# GD32H71x_72x register map
File version: 1.0
CPU: CM7 r1p2, little endian, MPU, FPU, 4 interrupt priority bits
Registers are 32-bit, read-write, reset 0x0 unless marked. A register's access mark holds for its fields unless they carry their own. Offsets are from the block's base; [hi:lo] are bit positions; {n}, {i} and the like mark numbered series.

## TIMER0 — Advanced-timers
Base 0x40010000
Same registers: TIMER7 0x40010400, TIMER19 0x40010800
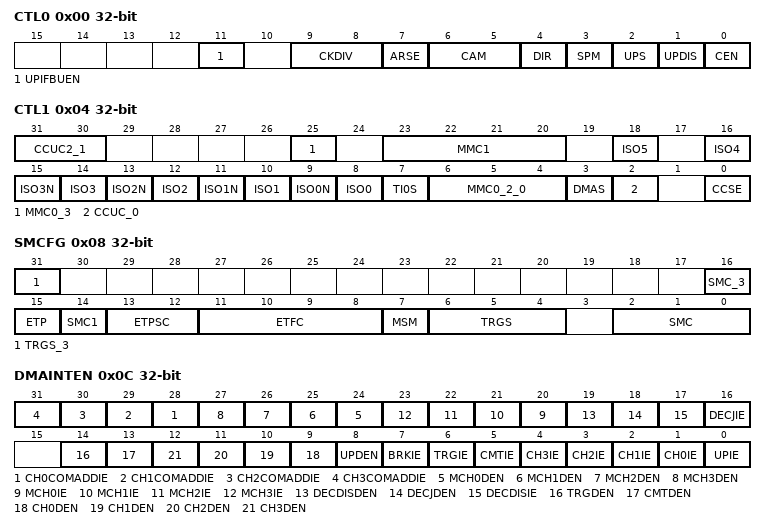
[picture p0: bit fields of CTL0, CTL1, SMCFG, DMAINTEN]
0x00 CTL0 — Control register 0
  [11] UPIFBUEN — UPIF bit backup enable
  [9:8] CKDIV — Clock division
  [7] ARSE — Auto-reload shadow enable
  [6:5] CAM — Counter align mode selection
  [4] DIR — Direction
  [3] SPM — Single pulse mode
  [2] UPS — Update source
  [1] UPDIS — Update disable
  [0] CEN — Counter enable
0x04 CTL1 — Control register 1
  [31:30] CCUC2_1 — Commutation control shadow register update control
  [25] MMC0_3 — Master mode control 0
  [23:20] MMC1 — Master mode control 1
  [18] ISO5 — Idle state of channel 5 output.
  [16] ISO4 — Idle state of channel 4 output.
  [15] ISO3N — Idle state of multi mode channel 3 complementary output.
  [14] ISO3 — Idle state of channel 3 output.
  [13] ISO2N — Idle state of multi mode channel 2 complementary output.
  [12] ISO2 — Idle state of channel 2 output
  [11] ISO1N — Idle state of multi mode channel 1 complementary output
  [10] ISO1 — Idle state of channel 1 output
  [9] ISO0N — Idle state of multi mode channel 0 complementary output
  [8] ISO0 — Idle state of channel 0 output
  [7] TI0S — Channel 0 trigger input selection
  [6:4] MMC0_2_0 — Master mode control 0
  [3] DMAS — DMA request source selection
  [2] CCUC_0 — Commutation control shadow register update control
  [0] CCSE — Commutation control shadow enable
0x08 SMCFG — Slave mode configuration register
  [31] TRGS_3 — Bit 3 of trigger selection
  [16] SMC_3 — Bit 3 of slave mode control
  [15] ETP — External trigger polarity
  [14] SMC1 — Part of SMC is used to enable external clock mode 1
  [13:12] ETPSC — External trigger prescaler
  [11:8] ETFC — External trigger filter control
  [7] MSM — Master-slave mode
  [6:4] TRGS — Trigger selection
  [2:0] SMC — Slave mode control
0x0C DMAINTEN — DMA and interrupt enable register
  [n+28] CH{n}COMADDIE (n=0..3) — Channel {n} additional compare interrupt enable
  [n+24] MCH{n}DEN (n=0..3) — Multi mode channel {n} capture/compare DMA request enable
  [n+20] MCH{n}IE (n=0..3) — Multi mode channel {n} capture/compare interrupt enable
  [19] DECDISDEN — Quadrature decoder signal disconnection detection enable
  [18] DECJDEN — Quadrature decoder signal jump (the two signals jump at the same time) detection enable
  [17] DECDISIE — Quadrature decoder signal disconnection interrupt enable
  [16] DECJIE — Quadrature decoder signal jump (the two signals jump at the same time) interrupt enable
  [14] TRGDEN — Trigger DMA request enable
  [13] CMTDEN — Commutation DMA request enable
  [n+9] CH{n}DEN (n=0..3) — Channel {n} capture/compare DMA request enable
  [8] UPDEN — Update DMA request enable
  [7] BRKIE — Break interrupt enable
  [6] TRGIE — Trigger interrupt enable
  [5] CMTIE — Commutation interrupt enable
  [n+1] CH{n}IE (n=0..3) — Channel {n} capture/compare interrupt enable
  [0] UPIE — Update interrupt enable
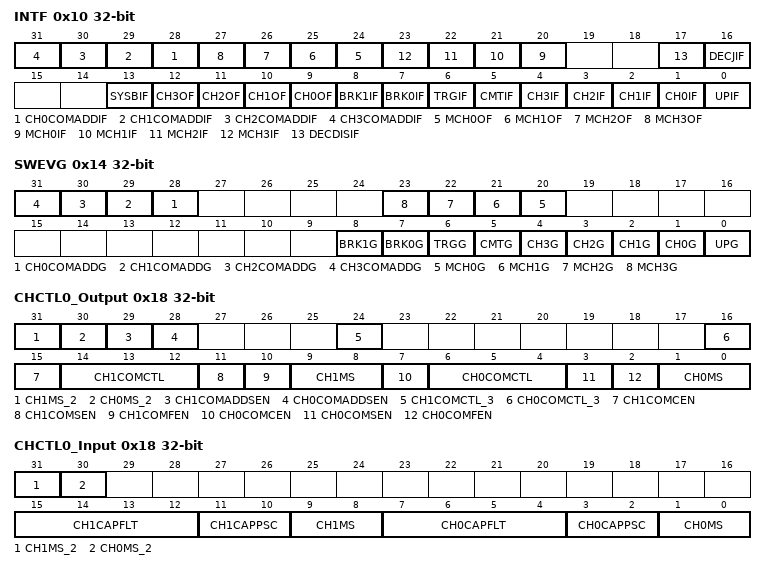
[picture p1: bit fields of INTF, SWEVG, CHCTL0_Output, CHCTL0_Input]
0x10 INTF — Interrupt flag register
  [n+28] CH{n}COMADDIF (n=0..3) — Channel {n} additional compare interrupt flag
  [n+24] MCH{n}OF (n=0..3) — Multi mode channel {n} over capture flag
  [n+20] MCH{n}IF (n=0..3) — Multi mode channel {n} capture/compare interrupt flag
  [17] DECDISIF — Quadrature decoder signal disconnection interrupt flag
  [16] DECJIF — Quadrature decoder signal jump (the two signals jump at the same time) interrupt flag
  [13] SYSBIF
  [n+9] CH{n}OF (n=0..3) — Channel {n} over capture flag
  [8] BRK1IF — Break1 interrupt flag
  [7] BRK0IF — Break0 interrupt flag
  [6] TRGIF — Trigger interrupt flag
  [5] CMTIF — Channel commutation interrupt flag
  [n+1] CH{n}IF (n=0..3) — Channel {n} capture/compare interrupt flag
  [0] UPIF — Update interrupt flag
0x14 SWEVG wo — Software event generation register
  [n+28] CH{n}COMADDG (n=0..3) — Channel {n} additional compare event generation
  [n+20] MCH{n}G (n=0..3) — Multi mode channel {n} capture or compare event generation
  [8] BRK1G — Break1 event generation
  [7] BRK0G — Break0 event generation
  [6] TRGG — Trigger event generation
  [5] CMTG — Channel commutation event generation
  [n+1] CH{n}G (n=0..3) — Channel {n} capture or compare event generation
  [0] UPG — Update event generation
0x18 CHCTL0_Output — Channel control register 0 (output mode)
  [31] CH1MS_2 — 2th bit of CH1MS
  [30] CH0MS_2 — 2th bit of CH0MS
  [29] CH1COMADDSEN — Channel 1 additional compare output shadow enable
  [28] CH0COMADDSEN — Channel 0 additional compare output shadow enable
  [24] CH1COMCTL_3 — Bit 3 of channel 1 compare output control
  [16] CH0COMCTL_3 — Bit 3 of channel 0 compare output control
  [15] CH1COMCEN — Channel 1 output compare clear enable
  [14:12] CH1COMCTL — Channel 1 compare output control
  [11] CH1COMSEN — Channel 1 output compare shadow enable
  [10] CH1COMFEN — Channel 1 output compare fast enable
  [9:8] CH1MS — Channel 1 mode selection
  [7] CH0COMCEN — Channel 0 output compare clear enable
  [6:4] CH0COMCTL — Channel 0 compare output control
  [3] CH0COMSEN — Channel 0 compare output shadow enable
  [2] CH0COMFEN — Channel 0 compare output fast enable
  [1:0] CH0MS — Channel 0 I/O mode selection
0x18 CHCTL0_Input (alternate view of CHCTL0_Output) — Channel control register 0 (input mode)
  [31] CH1MS_2 — 2th bit of CH1MS
  [30] CH0MS_2 — 2th bit of CH0MS
  [15:12] CH1CAPFLT — Channel 1 input capture filter control
  [11:10] CH1CAPPSC — Channel 1 input capture prescaler
  [9:8] CH1MS — Channel 1 mode selection
  [7:4] CH0CAPFLT — Channel 0 input capture filter control
  [3:2] CH0CAPPSC — Channel 0 input capture prescaler
  [1:0] CH0MS — Channel 0 mode selection
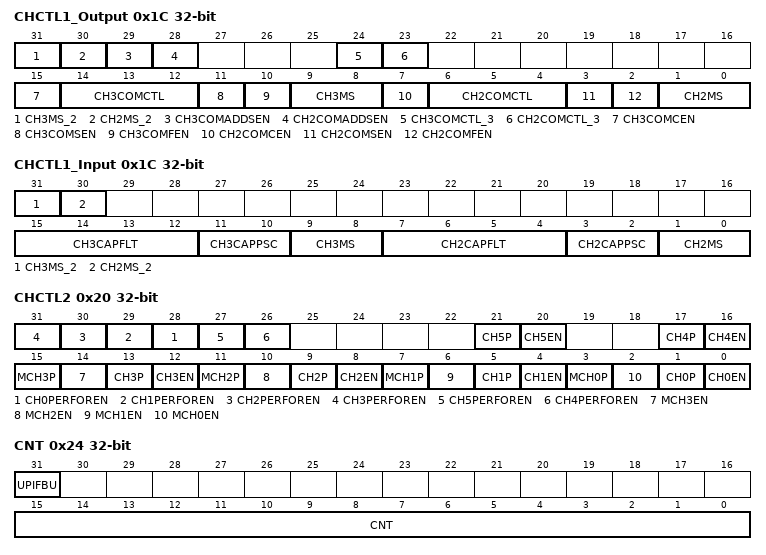
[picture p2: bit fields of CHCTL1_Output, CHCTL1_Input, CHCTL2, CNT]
0x1C CHCTL1_Output — Channel control register 1 (output mode)
  [31] CH3MS_2 — 2th bit of CH3MS
  [30] CH2MS_2 — 2th bit of CH2MS
  [29] CH3COMADDSEN — Channel 3 additional compare output shadow enable
  [28] CH2COMADDSEN — Channel 2 additional compare output shadow enable
  [24] CH3COMCTL_3 — BIT 3 of channel 3 compare output control
  [23] CH2COMCTL_3 — BIT 3 of channel 2 compare output control
  [15] CH3COMCEN — Channel 3 output compare clear enable
  [14:12] CH3COMCTL — Channel 3 compare output control
  [11] CH3COMSEN — Channel 3 output compare shadow enable
  [10] CH3COMFEN — Channel 3 output compare fast enable
  [9:8] CH3MS — Channel 3 mode selection
  [7] CH2COMCEN — Channel 2 output compare clear enable
  [6:4] CH2COMCTL — Channel 2 compare output control
  [3] CH2COMSEN — Channel 2 compare output shadow enable
  [2] CH2COMFEN — Channel 2 compare output fast enable
  [1:0] CH2MS — Channel 2 mode selection
0x1C CHCTL1_Input (alternate view of CHCTL1_Output) — Channel control register 1 (input mode)
  [31] CH3MS_2 — 2th bit of CH3MS
  [30] CH2MS_2 — 2th bit of CH2MS
  [15:12] CH3CAPFLT — Channel 3 input capture filter control
  [11:10] CH3CAPPSC — Channel 3 input capture prescaler
  [9:8] CH3MS — Channel 3 mode selection
  [7:4] CH2CAPFLT — Channel 2 input capture filter control
  [3:2] CH2CAPPSC — Channel 2 input capture prescaler
  [1:0] CH2MS — Channel 2 mode selection
0x20 CHCTL2 — Channel control register 2
  [n+28] CH{n}PERFOREN (n=0..3) — Channel {n} in the composite PWM mode or asymmetric PWM mode, the period point match moment O{n}CPRE level setting
  [27] CH5PERFOREN — Channel 5 in the composite PWM mode or asymmetric PWM mode, the period point match moment O5CPRE level setting
  [26] CH4PERFOREN — Channel 4 in the composite PWM mode or asymmetric PWM mode, the period point match moment O4CPRE level setting
  [4n+1] CH{n}P (n=0..5) — Channel {n} capture/compare polarity
  [4n] CH{n}EN (n=0..5) — Channel {n} capture/compare enable
  [15] MCH3P — Multi mode channel 3 capture/compare polarity
  [14] MCH3EN — Multi mode channel 3 capture/compare enable
  [11] MCH2P — Multi mode channel 2 output polarity
  [10] MCH2EN — Multi mode channel 2 output enable
  [7] MCH1P — Multi mode channel 1 output polarity
  [6] MCH1EN — Multi mode channel 1 output enable
  [3] MCH0P — Multi mode channel 0 output polarity
  [2] MCH0EN — Multi mode channel 0 capture/compare enable
0x24 CNT — counter
  [31] UPIFBU — UPIF bit backup
  [15:0] CNT — current counter value
0x28 PSC — prescaler
  [15:0] PSC — Prescaler value of the counter clock
0x2C CAR — Counter auto reload register
  [15:0] CARL — Counter auto reload value
0x30 CREP0 — Counter repetition register
  [7:0] CREP0 — Counter repetition value
0x34 CH0CV — Channel 0 capture/compare value register
  [15:0] CH0VAL — Capture or compare value of channel0
0x38 CH1CV — Channel 1 capture/compare value register
  [15:0] CH1VAL — Capture or compare value of channel1
0x3C CH2CV — Channel 2 capture/compare value register
  [15:0] CH2VAL — Capture or compare value of channel 2
0x40 CH3CV — Channel 3 capture/compare value register
  [15:0] CH3VAL — Capture or compare value of channel 3
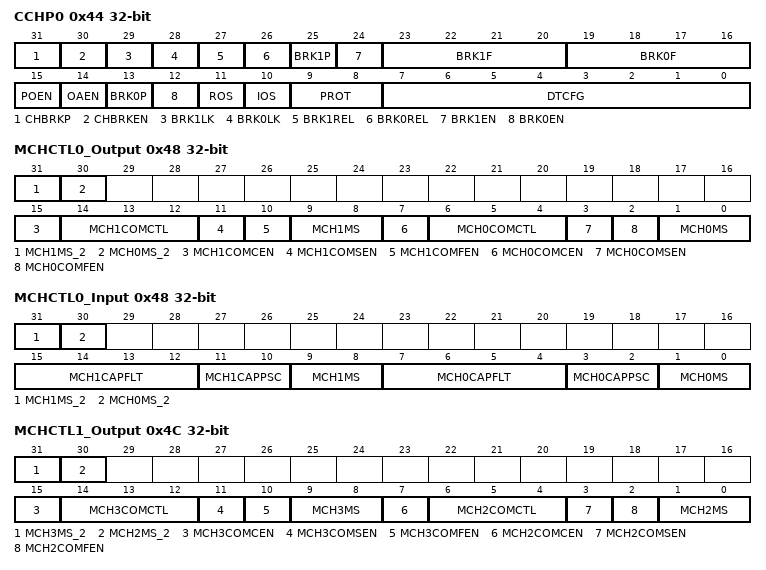
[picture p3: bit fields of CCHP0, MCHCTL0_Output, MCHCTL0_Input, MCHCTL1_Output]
0x44 CCHP0 — Complementary channel protection register 0
  [31] CHBRKP — Channel BREAK input signal polarity
  [30] CHBRKEN — Channel BREAK input signal enable
  [29] BRK1LK — BREAK1 input locked
  [28] BRK0LK — BREAK0 input locked
  [27] BRK1REL — BREAK1 input released
  [26] BRK0REL — BREAK0 input released
  [25] BRK1P — BREAK1 input signal polarity
  [24] BRK1EN — BREAK1 input signal enable
  [23:20] BRK1F — BREAK1 input signal filter
  [19:16] BRK0F — BREAK0 and channel BREAK input signal filter
  [15] POEN — Primary output enable
  [14] OAEN — Output automatic enable
  [13] BRK0P — BREAK0 input signal polarity
  [12] BRK0EN — BREAK0 input signal enable
  [11] ROS — Run mode off-state enable
  [10] IOS — Idle mode off-state enable
  [9:8] PROT — Complementary register protect control
  [7:0] DTCFG — Dead time configuration
0x48 MCHCTL0_Output — Multi mode channel control register 0 (output mode)
  [31] MCH1MS_2 — Multi mode channel 1 I/O mode selection
  [30] MCH0MS_2 — Multi mode channel 0 I/O mode selection
  [15] MCH1COMCEN — Multi mode channel 1 output compare clear enable
  [14:12] MCH1COMCTL — Multi mode channel 1 compare output control
  [11] MCH1COMSEN — Multi mode channel 1 output compare shadow enable
  [10] MCH1COMFEN — Multi mode channel 1 output compare fault enable
  [9:8] MCH1MS — Multi mode channel 1 I/O mode selection
  [7] MCH0COMCEN — Multi mode channel 0 output compare clear enable
  [6:4] MCH0COMCTL — Multi mode channel 0 output compare control
  [3] MCH0COMSEN — Multi mode channel 0 output compare shadow enable
  [2] MCH0COMFEN — Multi mode channel 0 output compare fault enable
  [1:0] MCH0MS — Multi mode channel 0 I/O mode selection
0x48 MCHCTL0_Input (alternate view of MCHCTL0_Output) — Multi mode channel control register 0 (input mode)
  [31] MCH1MS_2 — Multi mode channel 1 I/O mode selection
  [30] MCH0MS_2 — Multi mode channel 0 I/O mode selection
  [15:12] MCH1CAPFLT — Multi mode channel 1 input capture filter control
  [11:10] MCH1CAPPSC — Multi mode channel 1 input capture prescaler
  [9:8] MCH1MS — Multi mode channel 1 I/O mode selection
  [7:4] MCH0CAPFLT — Multi mode channel 0 input capture filter control
  [3:2] MCH0CAPPSC — Multi mode channel 0 input capture prescaler
  [1:0] MCH0MS — Multi mode channel 0 I/O mode selection
0x4C MCHCTL1_Output — Multi mode channel control register 1 (output mode)
  [31] MCH3MS_2 — 2th bit of MCH3MS
  [30] MCH2MS_2 — 2th bit of MCH2MS
  [15] MCH3COMCEN — Multi mode channel 3 output compare clear enable
  [14:12] MCH3COMCTL — Multi mode channel 3 compare output control
  [11] MCH3COMSEN — Multi mode channel 3 output compare shadow enable
  [10] MCH3COMFEN — Multi mode channel 3 output compare fast enable
  [9:8] MCH3MS — Multi mode channel 3 I/O mode selection
  [7] MCH2COMCEN — Multi mode channel 2 output compare clear enable
  [6:4] MCH2COMCTL — Multi mode channel 2 compare output control
  [3] MCH2COMSEN — Multi mode channel 2 output compare shadow enable
  [2] MCH2COMFEN — Multi mode channel 2 output compare fast enable
  [1:0] MCH2MS — Multi mode channel 2 I/O mode selection
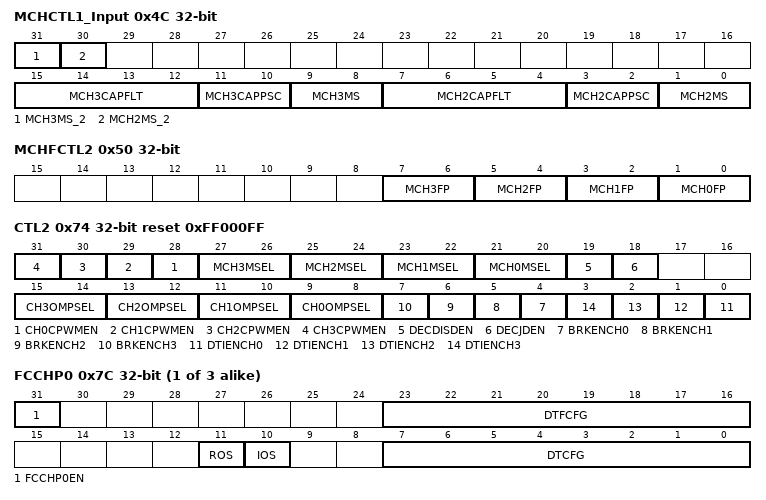
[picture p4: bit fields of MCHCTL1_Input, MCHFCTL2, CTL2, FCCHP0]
0x4C MCHCTL1_Input (alternate view of MCHCTL1_Output) — Multi mode channel control register 1(input mode)
  [31] MCH3MS_2 — 2th bit of MCH3MS
  [30] MCH2MS_2 — 2th bit of MCH2MS
  [15:12] MCH3CAPFLT — Multi mode channel 3 input capture filter control
  [11:10] MCH3CAPPSC — Multi mode channel 3 input capture prescaler
  [9:8] MCH3MS — Multi mode channel 3 I/O mode selection.
  [7:4] MCH2CAPFLT — Multi mode channel 2 input capture filter control
  [3:2] MCH2CAPPSC — Multi mode channel 2 input capture prescaler
  [1:0] MCH2MS — Multi mode channel 2 I/O mode selection
0x50 MCHFCTL2 — Multi mode channel control register 2
  [2n+1:2n] MCH{n}FP (n=0..3) — Multi mode channel {n} capture/compare free polarity
{0x54+4i} MCH{i}CV (i=0..2) — Multi mode channel {i} capture/compare value register
  [15:0] MCH{i}VAL — Capture/compare value of multi mode channel {i}
0x60 MCH3CV — Capture/compare value of multi mode channel 3
  [15:0] MCH3VAL — Capture/compare value of channel 3
{0x64+4i} CH{i}COMV_ADD (i=0..3) — Channel {i} additional compare value register
  [15:0] CH{i}COMVAL_ADD — Additional compare value of channel {i}
0x74 CTL2 reset 0xFF000FF — Control register 2
  [n+28] CH{n}CPWMEN (n=0..3) — Channel {n} composite PWM mode enable
  [2n+21:2n+20] MCH{n}MSEL (n=0..3) — Multi mode channel {n} mode select
  [19] DECDISDEN — Quadrature decoder signal disconnection detection enable
  [18] DECJDEN — Quadrature decoder signal jump (the two signals jump at the same time) detection enable
  [2n+9:2n+8] CH{n}OMPSEL (n=0..3) — Channel {n} output match pulse select
  [n+4] BRKENCH{n} (n=0..3) — Break control enable for channel {n}
  [n] DTIENCH{n} (n=0..3) — Dead time inserted enable for channel {n}
{0x7C+4i} FCCHP{i} (i=0..2) — Free complementary channel protection register {i}
  [31] FCCHP{i}EN — Free complementary channel protection register {i} enable
  [23:16] DTFCFG — Dead time falling edge configure
  [11] ROS — Run mode off-state enable
  [10] IOS — Idle mode off-state enable
  [7:0] DTCFG — Dead time configure
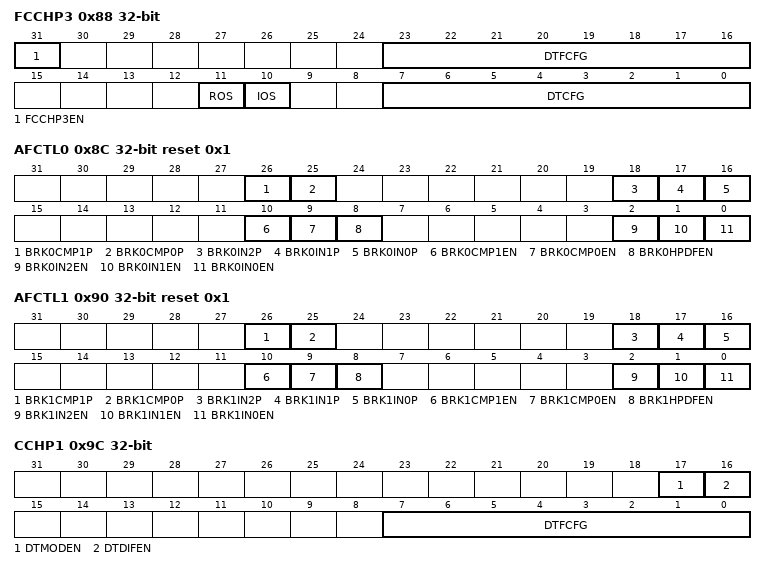
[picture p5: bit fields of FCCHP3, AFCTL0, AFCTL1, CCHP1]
0x88 FCCHP3 — Free complementary channel protection register 3
  [31] FCCHP3EN — Free complementary channel protection register 0 enable
  [23:16] DTFCFG — Dead time falling edge configure
  [11] ROS — Run mode off-state enable
  [10] IOS — Idle mode off-state enable
  [7:0] DTCFG — Dead time configure
0x8C AFCTL0 reset 0x1 — alternate function control register 0
  [26] BRK0CMP1P — BRK CMP1 input polarity
  [25] BRK0CMP0P — BRK CMP0 input polarity
  [18] BRK0IN2P — BREAK0 BRKIN2 alternate function input polarity
  [17] BRK0IN1P — BREAK0 BRKIN1 alternate function input polarity
  [16] BRK0IN0P — BREAK0 BRKIN0 alternate function input polarity
  [10] BRK0CMP1EN — BRK CMP1 enable
  [9] BRK0CMP0EN — BRK CMP0 enable
  [8] BRK0HPDFEN — BRK HPDF input enable
  [2] BRK0IN2EN — BREAK0 BRKIN2 alternate function input enable
  [1] BRK0IN1EN — BREAK0 BRKIN1 alternate function input enable
  [0] BRK0IN0EN — BREAK0 BRKIN0 alternate function input enable
0x90 AFCTL1 reset 0x1 — alternate function control register 0
  [26] BRK1CMP1P — BRK1 CMP1 input polarity
  [25] BRK1CMP0P — BRK1 CMP0 input polarity
  [18] BRK1IN2P — BREAK1 BRKIN2 alternate function input polarity
  [17] BRK1IN1P — BREAK1 BRKIN1 alternate function input polarity
  [16] BRK1IN0P — BRK1 BRKIN0 alternate function input polarity
  [10] BRK1CMP1EN — BRK1 CMP1 enable
  [9] BRK1CMP0EN — BRK1 CMP0 enable
  [8] BRK1HPDFEN — BRK1 HPDF input enable
  [2] BRK1IN2EN — BREAK1 BRKIN1 alternate function input enable
  [1] BRK1IN1EN — BREAK1 BRKIN1 alternate function input enable
  [0] BRK1IN0EN — BRK1 BRK1IN alternate function input enable
0x94 WDGPER — Watchdog counter register
  [31:0] WDGPER — Watchdog timeout count
0x98 CREP1 — Counter repetition register 1
  [31:0] CREP1 — Counter repetition value 1
0x9C CCHP1 — Complementary channel protection register 1
  [17] DTMODEN — Dead time modified on-the-fly enable
  [16] DTDIFEN — Dead time configure different enable
  [7:0] DTFCFG — Dead time falling edge configure
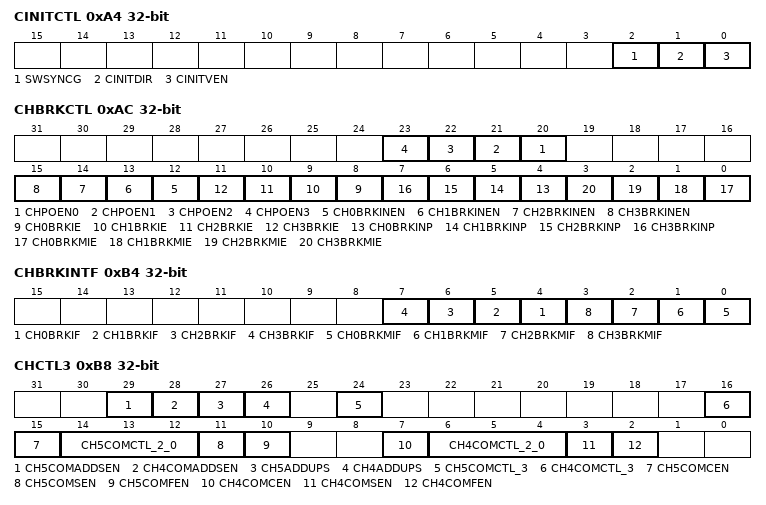
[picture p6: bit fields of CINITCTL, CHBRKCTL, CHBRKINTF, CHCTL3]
0xA4 CINITCTL access per field — Counter initial control register
  [2] SWSYNCG wo — Soft synchronization event generation
  [1] CINITDIR rw — Counter initial count direction
  [0] CINITVEN rw — Counter initial value register enable
0xA8 CINITV — Counter initial value register
  [15:0] CINITVAL — Counter initial value
0xAC CHBRKCTL — Channel break control register
  [n+20] CHPOEN{n} (n=0..3) — Channel primary output enable {n}
  [n+12] CH{n}BRKINEN (n=0..3) — Channel {n} BREAK input signal enable
  [n+8] CH{n}BRKIE (n=0..3) — Channel {n} BREAK interrupt enable
  [n+4] CH{n}BRKINP (n=0..3) — Channel {n} BREAK input signal polarity
  [n] CH{n}BRKMIE (n=0..3) — Channel {n} BREAK multi-period interrupt enable
0xB0 CHBRKPER — Channel break period register
  [15:0] PERCNT — Channel BREAK period count
0xB4 CHBRKINTF — Channel break interrupt flag register
  [n+4] CH{n}BRKIF (n=0..3) — Channel {n} BREAK interrupt flag
  [n] CH{n}BRKMIF (n=0..3) — Channel {n} BREAK multi-period interrupt flag
0xB8 CHCTL3 — Channel control register 3
  [29] CH5COMADDSEN — Channel 5 additional compare output shadow enable
  [28] CH4COMADDSEN — Channel 4 additional compare output shadow enable
  [27] CH5ADDUPS — Channel 5 additional update source
  [26] CH4ADDUPS — Channel 4 additional update source
  [24] CH5COMCTL_3 — Channel 5 compare output control
  [16] CH4COMCTL_3 — Channel 4 compare output control
  [15] CH5COMCEN — Channel 5 output compare clear enable
  [14:12] CH5COMCTL_2_0 — Channel 5 compare output control
  [11] CH5COMSEN — Channel 5 output compare shadow enable
  [10] CH5COMFEN — Channel 5 output compare fast enable
  [7] CH4COMCEN — Channel 4 output compare clear enable
  [6:4] CH4COMCTL_2_0 — Channel 4 compare output control
  [3] CH4COMSEN — Channel 4 compare output shadow enable
  [2] CH4COMFEN — Channel 4 output compare fast enable
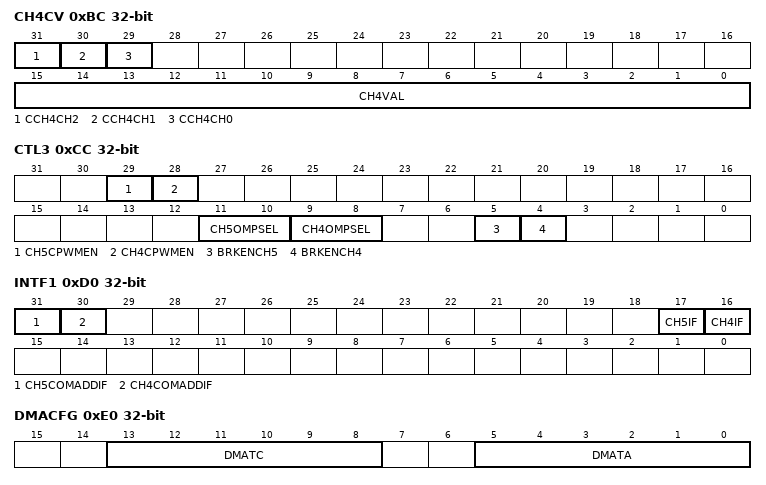
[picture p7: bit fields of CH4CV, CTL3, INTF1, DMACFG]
0xBC CH4CV — Channel 4 capture/compare value register
  [31] CCH4CH2 — Combine Channel 4 and Channel 2
  [30] CCH4CH1 — Combine Channel 4 and Channel 1
  [29] CCH4CH0 — Combine Channel 4 and Channel 0
  [15:0] CH4VAL — Capture or compare value of channel 4
0xC0 CH5CV — Channel 5 capture/compare value register
  [15:0] CH5VAL — Capture or compare value of channel 5
0xC4 CH4COMV_ADD — Channel 4 additional compare value register
  [15:0] CH4COMVAL_ADD — Additional compare value of channel 4
0xC8 CH5COMV_ADD — Channel 5 additional compare value register
  [15:0] CH5COMVAL_ADD — Additional compare value of channel 5
0xCC CTL3 — Control register 3
  [29] CH5CPWMEN — Channel 5 composite PWM mode enable
  [28] CH4CPWMEN — Channel 4 composite PWM mode enable
  [11:10] CH5OMPSEL — Channel 5 output match pulse select
  [9:8] CH4OMPSEL — Channel 4 output match pulse select
  [5] BRKENCH5 — Break control enable for channel 5
  [4] BRKENCH4 — Break control enable for channel 4
0xD0 INTF1 — Interrupt flag register 1
  [31] CH5COMADDIF — Channel 5 additional compare interrupt flag.
  [30] CH4COMADDIF — Channel 4 additional compare interrupt flag.
  [17] CH5IF — Channel 5 capture/compare interrupt flag
  [16] CH4IF — Channel 4 capture/compare interrupt flag
0xE0 DMACFG — DMA configuration register
  [13:8] DMATC — DMA transfer count
  [5:0] DMATA — DMA transfer access start address
0xE4 DMATB — DMA transfer buffer register
  [31:0] DMATB — DMA transfer buffer
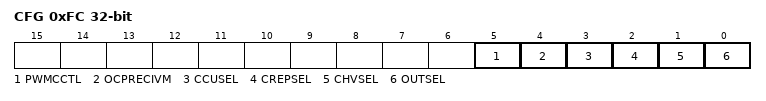
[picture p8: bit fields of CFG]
0xFC CFG — Configuration register
  [5] PWMCCTL — PWM mode change control
  [4] OCPRECIVM — Output prepare signal clear invalid mode select
  [3] CCUSEL — Commutation control shadow register update select
  [2] CREPSEL — The counter repetition register select
  [1] CHVSEL — Write CHxVAL register selection bit
  [0] OUTSEL — The output value selection bit
